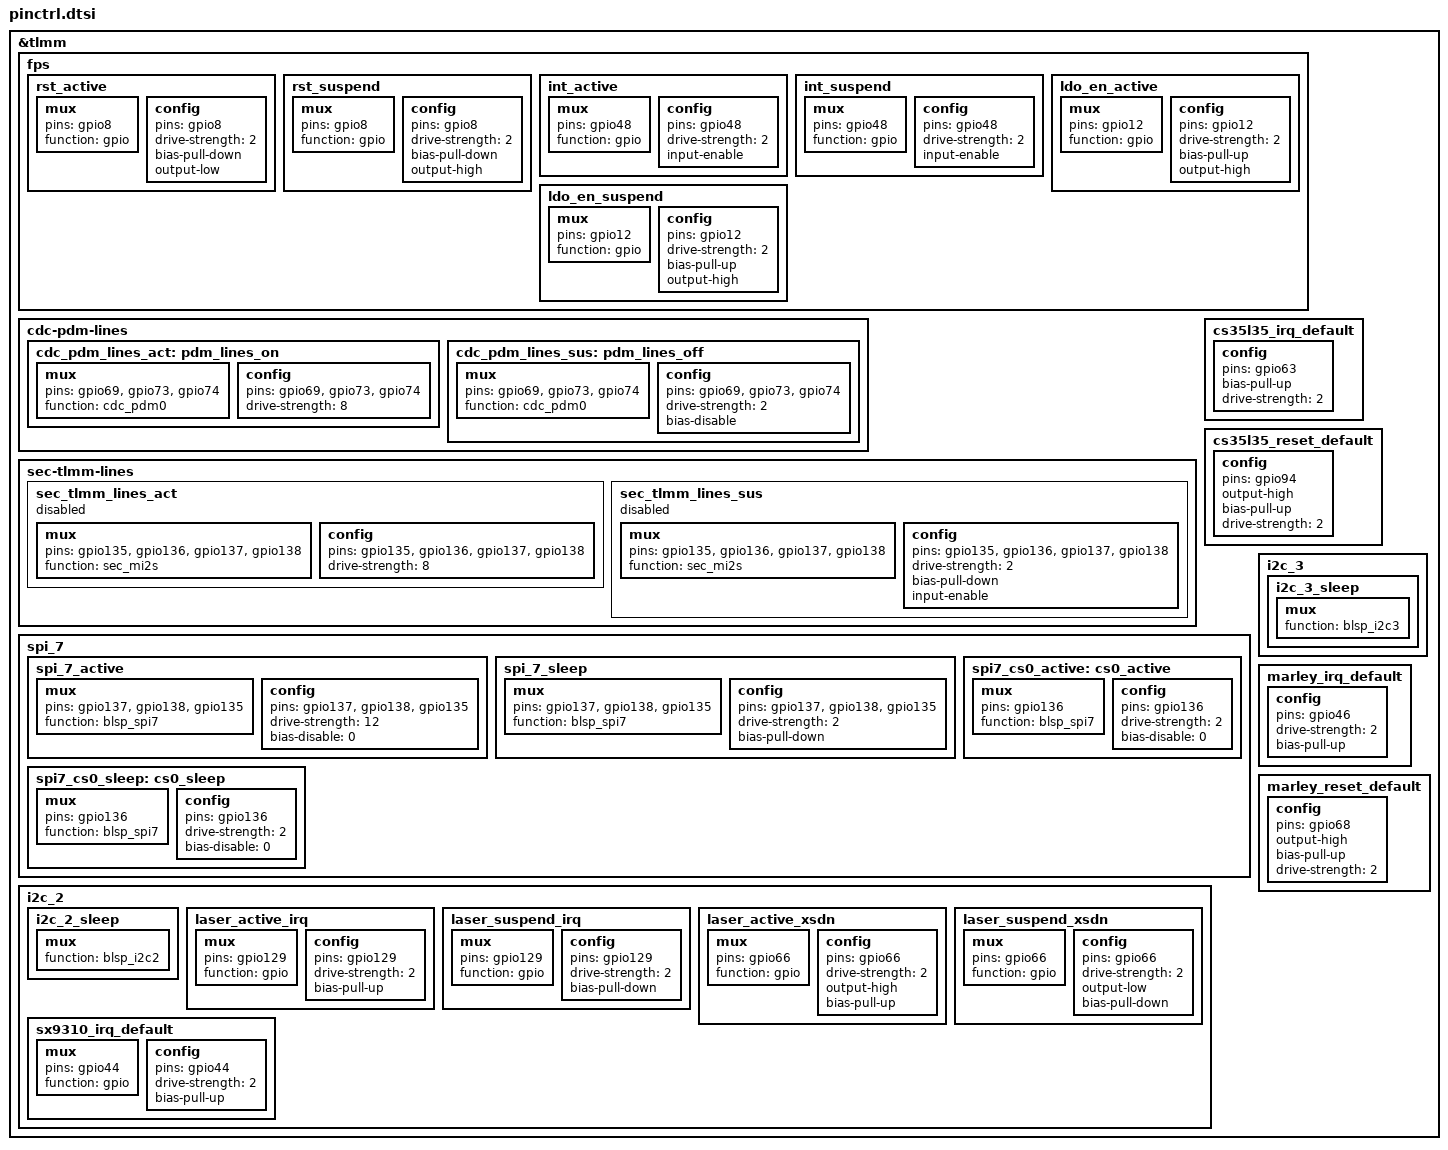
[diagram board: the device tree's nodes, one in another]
/* Copyright (c) 2018, Motorola Mobility Inc. All rights reserved.
 *
 * This program is free software; you can redistribute it and/or modify
 * it under the terms of the GNU General Public License version 2 and
 * only version 2 as published by the Free Software Foundation.
 *
 * This program is distributed in the hope that it will be useful,
 * but WITHOUT ANY WARRANTY; without even the implied warranty of
 * MERCHANTABILITY or FITNESS FOR A PARTICULAR PURPOSE.  See the
 * GNU General Public License for more details.
 */

/delete-node/ &hsuart_active;
/delete-node/ &hsuart_sleep;
/delete-node/ &blsp2_uart0_active;
/delete-node/ &blsp2_uart0_sleep;

&tlmm{

	fps: fps {
		rst_active: rst_active {
			/* RESET */
			mux {
				pins = "gpio8";
				function = "gpio";
			};

			config {
				pins = "gpio8";
				drive-strength = <2>; /* 2 MA */
				bias-pull-down; /* pull down */
				output-low;
			};
		};

		rst_suspend: rst_suspend{
			/* RESET */
			mux {
				pins = "gpio8";
				function = "gpio";
			};

			config {
				pins = "gpio8";
				drive-strength = <2>; /* 2 MA */
				bias-pull-down; /* pull down */
				output-high;
			};
		};

		int_active: int_active {
			/* INTERRUPT */
			mux {
				pins = "gpio48";
				function = "gpio";
			};

			config {
				pins = "gpio48";
				drive-strength = <2>; /* 2 MA */
				input-enable;
			};
		};

		int_suspend: int_suspend{
			/* INTERRUPT */
			mux {
				pins = "gpio48";
				function = "gpio";
			};

			config {
				pins = "gpio48";
				drive-strength = <2>; /* 2 MA */
				input-enable;
			};
		};

		ldo_en_active: ldo_en_active {
			/* LDO ENABLE */
			mux {
				pins = "gpio12";
				function = "gpio";
			};

			config {
				pins = "gpio12";
				drive-strength = <2>; /* 2 MA */
				bias-pull-up; /* pull up */
				output-high;
			};
		};

		ldo_en_suspend: ldo_en_suspend {
			/* LDO ENABLE */
			mux {
				pins = "gpio12";
				function = "gpio";
			};

			config {
				pins = "gpio12";
				drive-strength = <2>; /* 2 MA */
				bias-pull-up; /* pull up */
				output-high;
			};
		};

	};

	/delete-node/ cdc-pdm-lines;
	cdc-pdm-lines {
		cdc_pdm_lines_act: pdm_lines_on {
			mux {
				pins = "gpio69", "gpio73", "gpio74";
				function = "cdc_pdm0";
			};

			config {
				pins = "gpio69", "gpio73", "gpio74";
				drive-strength = <8>;
			};
		};

		cdc_pdm_lines_sus: pdm_lines_off {
			mux {
				pins = "gpio69", "gpio73", "gpio74";
				function = "cdc_pdm0";
			};

			config {
				pins = "gpio69", "gpio73", "gpio74";
				drive-strength = <2>;
				bias-disable;
			};
		};
	};
	sec-tlmm-lines {
		sec_tlmm_lines_act: sec_tlmm_lines_act {
			mux {
				pins = "gpio135", "gpio136",
					"gpio137", "gpio138";
				function = "sec_mi2s";
			};

			config {
				pins = "gpio135", "gpio136",
					"gpio137", "gpio138";
				drive-strength = <8>;
			};
		};

		sec_tlmm_lines_sus: sec_tlmm_lines_sus {
			mux {
				pins = "gpio135", "gpio136",
					"gpio137", "gpio138";
				function = "sec_mi2s";
			};
			config {
				pins = "gpio135", "gpio136",
					"gpio137", "gpio138";
				drive-strength = <2>;
				bias-pull-down;
				input-enable;
			};
		};
	};

	cs35l35_irq_default: cs35l35_irq_default {
		config {
			pins = "gpio63";
			bias-pull-up;
			drive-strength = <2>;
		};
	};

	cs35l35_reset_default: cs35l35_reset_default {
		config {
			pins = "gpio94";
			output-high;
			bias-pull-up;
			drive-strength = <2>;
		};
	};

	sec-tlmm-lines {
		sec_tlmm_lines_act: sec_tlmm_lines_act {
			status = "disabled";
		};

		sec_tlmm_lines_sus: sec_tlmm_lines_sus {
			status = "disabled";
		};
	};

	spi_7 {
		spi_7_active: spi_7_active {
			mux {
				/* MOSI, MISO, CLK */
				pins = "gpio137", "gpio138", "gpio135";
				function = "blsp_spi7";
			};

			config {
				pins = "gpio137", "gpio138", "gpio135";
				drive-strength = <12>; /* 12 MA */
				bias-disable = <0>; /* No PULL */
			};
		};

		spi_7_sleep: spi_7_sleep {
			mux {
				/* MOSI, MISO, CLK */
				pins = "gpio137", "gpio138", "gpio135";
				function = "blsp_spi7";
			};

			config {
				pins = "gpio137", "gpio138", "gpio135";
				drive-strength = <2>; /* 2 MA */
				bias-pull-down; /* PULL Down */
			};
		};

		spi7_cs0_active: cs0_active {
			mux {
				pins = "gpio136";
				function = "blsp_spi7";
			};

			config {
				pins = "gpio136";
				drive-strength = <2>;
				bias-disable = <0>;
			};
		};

		spi7_cs0_sleep: cs0_sleep {
			mux {
				pins = "gpio136";
				function = "blsp_spi7";
			};

			config {
				pins = "gpio136";
				drive-strength = <2>;
				bias-disable = <0>;
			};
		};
	};

	i2c_2 {
		i2c_2_sleep {
			mux {
				function = "blsp_i2c2";
			};
		};
	};

	i2c_3 {
		i2c_3_sleep {
			mux {
				function = "blsp_i2c3";
			};
		};
	};

	i2c_2 {
		laser_active_irq: laser_active_irq {
			mux {
				pins = "gpio129";
				function = "gpio";
			};

			config {
				pins = "gpio129";
				drive-strength = <2>;
				bias-pull-up; /* PULL UP */
			};
		};
		laser_suspend_irq: laser_suspend_irq {
			mux {
				pins = "gpio129";
				function = "gpio";
			};

			config {
				pins = "gpio129";
				drive-strength = <2>;
				bias-pull-down; /* PULL DOWN */
			};
		};
		laser_active_xsdn: laser_active_xsdn {
			mux {
				pins = "gpio66";
				function = "gpio";
			};

			config {
				pins = "gpio66";
				drive-strength = <2>;
				output-high;
				bias-pull-up; /* PULL UP */
			};
		};
		laser_suspend_xsdn: laser_suspend_xsdn {
			mux {
				pins = "gpio66";
				function = "gpio";
			};

			config {
				pins = "gpio66";
				drive-strength = <2>;
				output-low;
				bias-pull-down; /* PULL DOWN */
			};
		};

		sx9310_irq_default: sx9310_irq_default {  //cap sense inturrupt
			mux {
				pins = "gpio44";
				function = "gpio";
			};

			config {
				pins = "gpio44";
				drive-strength = <2>;
				bias-pull-up;
			};
		};
	};

	marley_irq_default: marley_irq_default {
		config {
			pins = "gpio46";
			drive-strength = <2>;
			bias-pull-up;
		};
	};

	marley_reset_default: marley_reset_default {
		config {
			pins = "gpio68";
			output-high;
			bias-pull-up;
			drive-strength = <2>;
		};
	};
};
